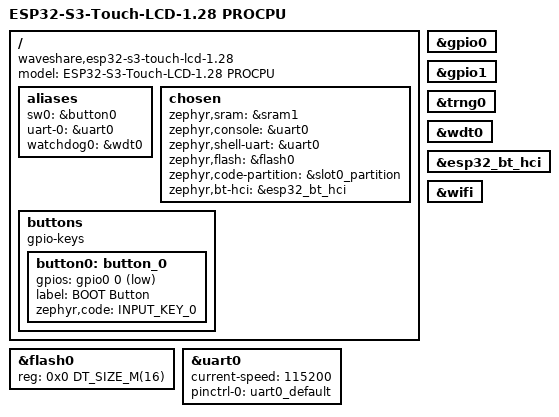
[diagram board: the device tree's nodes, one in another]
/*
 * Copyright (c) 2024 Joel Guittet
 * SPDX-License-Identifier: Apache-2.0
 */

/dts-v1/;
#include <espressif/esp32s3/esp32s3_r2.dtsi>
#include "esp32s3_touch_amoled_1_75-pinctrl.dtsi"
#include <zephyr/dt-bindings/display/panel.h>
#include <zephyr/dt-bindings/input/input-event-codes.h>
#include <espressif/partitions_0x0_amp_16M.dtsi>

/ {
	model = "ESP32-S3-Touch-LCD-1.28 PROCPU";
	compatible = "waveshare,esp32-s3-touch-lcd-1.28";

	aliases {
		sw0 = &button0;
		uart-0 = &uart0;
		watchdog0 = &wdt0;
	};

	chosen {
		zephyr,sram = &sram1;
		zephyr,console = &uart0;
		zephyr,shell-uart = &uart0;
		zephyr,flash = &flash0;
		zephyr,code-partition = &slot0_partition;
		zephyr,bt-hci = &esp32_bt_hci;
	};

	/* Buttons */
	buttons {
		compatible = "gpio-keys";
		button0: button_0 {
			gpios = <&gpio0 0 (GPIO_PULL_UP | GPIO_ACTIVE_LOW)>;
			label = "BOOT Button";
			zephyr,code = <INPUT_KEY_0>;
		};
	};
};

&flash0 {
	reg = <0x0 DT_SIZE_M(16)>;
};

&gpio0 {
	status = "okay";
};

&gpio1 {
	status = "okay";
};

&trng0 {
	status = "okay";
};

&uart0 {
	status = "okay";
	current-speed = <115200>;
	pinctrl-0 = <&uart0_default>;
	pinctrl-names = "default";
};

&wdt0 {
	status = "okay";
};

&esp32_bt_hci {
	status = "okay";
};

&wifi {
	status = "okay";
};
